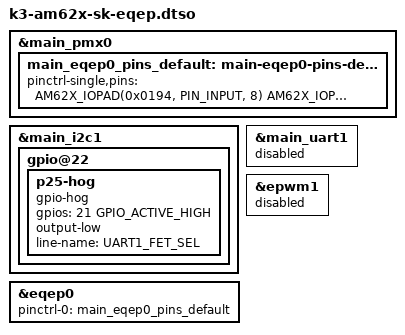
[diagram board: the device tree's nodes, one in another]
// SPDX-License-Identifier: GPL-2.0
/*
 * DT Overlay for enabling EQEP on AM625-SK, AM62 LP-SK, and AM62A7-SK
 *
 * Copyright (C) 2023 Texas Instruments Incorporated - https://www.ti.com/
 */

/dts-v1/;
/plugin/;

#include <dt-bindings/gpio/gpio.h>
#include "k3-pinctrl.h"

&main_pmx0 {
	main_eqep0_pins_default: main-eqep0-pins-default {
		pinctrl-single,pins = <
			AM62X_IOPAD(0x0194, PIN_INPUT, 8) /* (B19/C19) MCASP0_AXR3.EQEP0_A */
			AM62X_IOPAD(0x0198, PIN_INPUT, 8) /* (A19/B19) MCASP0_AXR2.EQEP0_B */
			AM62X_IOPAD(0x01a0, PIN_INPUT, 8) /* (E18/B20) MCASP0_AXR0.EQEP0_I */
			AM62X_IOPAD(0x019c, PIN_INPUT, 8) /* (B18/B18) MCASP0_AXR1.EQEP0_S */
		>;
	};
};

&main_i2c1 {
	gpio@22 {
		p25-hog {
			/* P25 - UART1_FET_SEL */
			gpio-hog;
			gpios = <21 GPIO_ACTIVE_HIGH>;
			output-low;
			line-name = "UART1_FET_SEL";
		};
	};
};

&main_uart1 {
	/* Conflict: MCASP0_AXR3, MCASP0_AXR2 */
	status = "disabled";
};

&epwm1 {
	/* Conflict: MCASP0_AXR0, MCASP0_AXR1 */
	status = "disabled";
};

&eqep0 {
	status = "okay";
	/* AM62: J3: A=P38/B=P35 */
	/* AM62A: J3: A=P40/B=P38 */
	pinctrl-names = "default";
	pinctrl-0 = <&main_eqep0_pins_default>;
};
